# VPAC0_DRU_UTC_VPAC0_DRU_MMR_CFG_DRU_DRU_CHRT register map
Vendor: Texas Instruments
Peripheral module from a debugger description file (folder J7ES).
Registers are 64-bit, access per field, reset 0x0 unless marked. A register's access mark holds for its fields unless they carry their own. Offsets are as the file gives them; lines under a group give offsets from that group; [hi:lo] are bit positions; {n}, {i} and the like mark numbered series; 'fields as' and 'values as' point back to an identical list; <NAME> marks a mode.

## VPAC0_DRU_UTC_VPAC0_DRU_MMR_CFG_DRU_DRU_CHRT
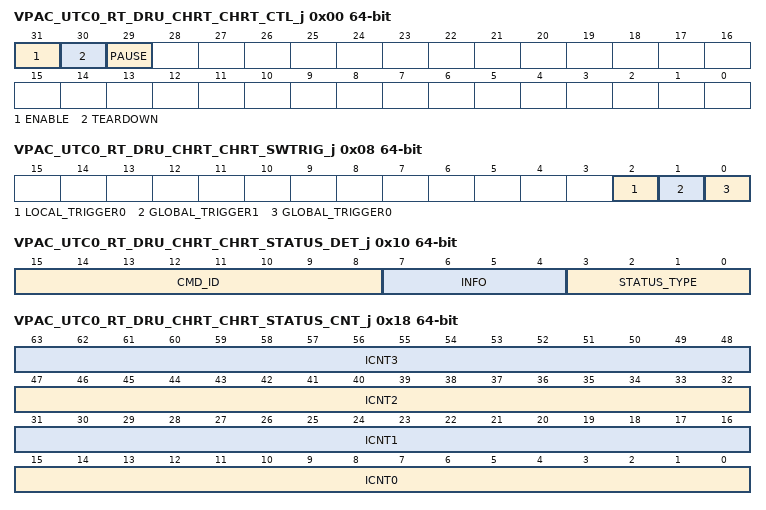
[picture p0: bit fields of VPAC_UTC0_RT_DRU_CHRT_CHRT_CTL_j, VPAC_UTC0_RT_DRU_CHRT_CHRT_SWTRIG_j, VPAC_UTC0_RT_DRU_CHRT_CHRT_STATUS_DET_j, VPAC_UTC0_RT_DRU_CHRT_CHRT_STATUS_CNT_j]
0x00 VPAC_UTC0_RT_DRU_CHRT_CHRT_CTL_j — The channel realtime control register contains real-time cotrol and status information for the DMA Channel. The fields in this regsiter can be changed while the channel is in operation. Offset = 00260000h + (j * 100h); where j = 0h to 1Fh
  [31] ENABLE rw — This field enables or disables the channel.
  [30] TEARDOWN rw — Channel teardown: Setting this bit will request the channel to be torn down.
  [29] PAUSE rw — Channel pause: Setting this bit will request the channel to pause processing at the next packet boundary.
0x08 VPAC_UTC0_RT_DRU_CHRT_CHRT_SWTRIG_j — The Software Trigger Register provides a mechanism by which software can directly trigger the channel in a secure way. Offset = 00260008h + (j * 100h); where j = 0h to 1Fh
  [2] LOCAL_TRIGGER0 rw — Trigger: writing this bit with a value of 1 will cause the trigger event to be sent to this channel.
  [1] GLOBAL_TRIGGER1 rw — Trigger: writing this bit with a value of 1 will cause the trigger event to be sent to this channel.
  [0] GLOBAL_TRIGGER0 rw — Trigger: writing this bit with a value of 1 will cause the trigger event to be sent to this channel.
0x10 VPAC_UTC0_RT_DRU_CHRT_CHRT_STATUS_DET_j ro — The channel status details Offset = 00260010h + (j * 100h); where j = 0h to 1Fh
  [15:8] CMD_ID — The last cmd_id given to the write queue
  [7:4] INFO — The info of the error that was received
  [3:0] STATUS_TYPE — The type of error that was received
0x18 VPAC_UTC0_RT_DRU_CHRT_CHRT_STATUS_CNT_j ro — The channel count details Offset = 00260018h + (j * 100h); where j = 0h to 1Fh
  [16n+15:16n] ICNT{n} (n=0..3) — The last icnt{n} given to the write queue
